VERSION "HIPBNYYYYYYYYYYYYYYYYYYYYYYYYYYYNNNYNNNNNN/4/%%%/4/'%**4NNN///"

NS_ :

BS_:

BU_: NodeD2 NodeC2 NodeB2 NodeA2 NodeD NodeC NodeB NodeA

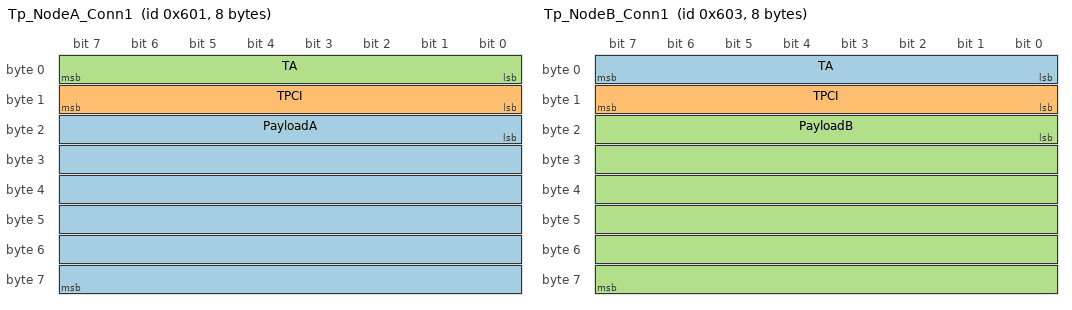
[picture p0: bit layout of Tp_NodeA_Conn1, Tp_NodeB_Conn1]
BO_ 1537 Tp_NodeA_Conn1: 8 NodeA
 SG_ PayloadA : 16|48@1+ (1,0) [0|0] "" Vector__XXX
 SG_ TPCI : 8|8@1+ (1,0) [0|0] "" Vector__XXX
 SG_ TA : 0|8@1+ (1,0) [0|0] "" Vector__XXX

BO_ 1539 Tp_NodeB_Conn1: 8 NodeB
 SG_ TA : 0|8@1+ (1,0) [0|0] "" Vector__XXX
 SG_ TPCI : 8|8@1+ (1,0) [0|0] "" Vector__XXX
 SG_ PayloadB : 16|48@1+ (1,0) [0|0] "" Vector__XXX

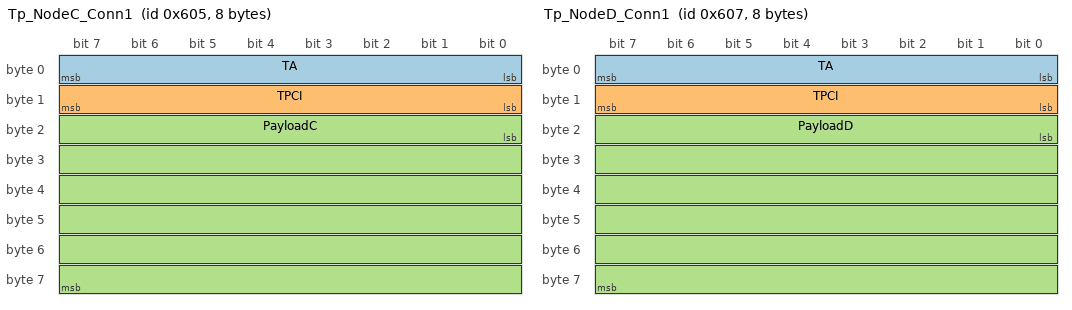
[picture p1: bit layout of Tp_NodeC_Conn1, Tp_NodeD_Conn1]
BO_ 1541 Tp_NodeC_Conn1: 8 NodeC
 SG_ TA : 0|8@1+ (1,0) [0|0] "" Vector__XXX
 SG_ TPCI : 8|8@1+ (1,0) [0|0] "" Vector__XXX
 SG_ PayloadC : 16|48@1+ (1,0) [0|0] "" Vector__XXX

BO_ 1543 Tp_NodeD_Conn1: 8 NodeD
 SG_ TA : 0|8@1+ (1,0) [0|0] "" Vector__XXX
 SG_ TPCI : 8|8@1+ (1,0) [0|0] "" Vector__XXX
 SG_ PayloadD : 16|48@1+ (1,0) [0|0] "" Vector__XXX

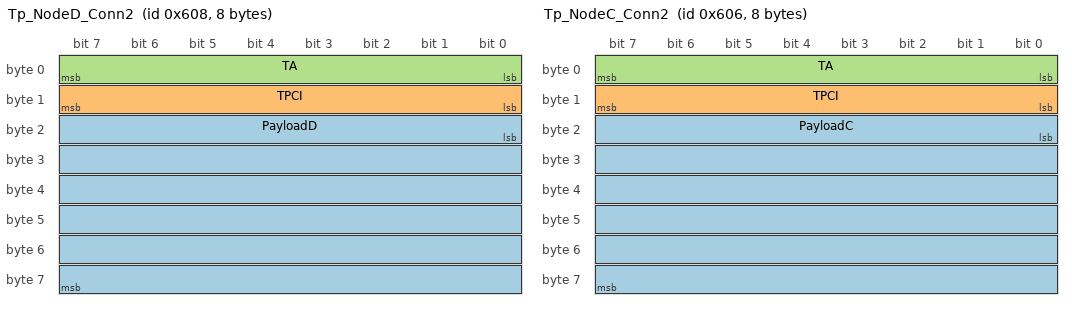
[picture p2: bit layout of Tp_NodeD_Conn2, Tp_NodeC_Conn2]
BO_ 1544 Tp_NodeD_Conn2: 8 NodeD
 SG_ PayloadD : 16|48@1+ (1,0) [0|0] "" Vector__XXX
 SG_ TPCI : 8|8@1+ (1,0) [0|0] "" Vector__XXX
 SG_ TA : 0|8@1+ (1,0) [0|0] "" Vector__XXX

BO_ 1542 Tp_NodeC_Conn2: 8 NodeC
 SG_ PayloadC : 16|48@1+ (1,0) [0|0] "" Vector__XXX
 SG_ TPCI : 8|8@1+ (1,0) [0|0] "" Vector__XXX
 SG_ TA : 0|8@1+ (1,0) [0|0] "" Vector__XXX

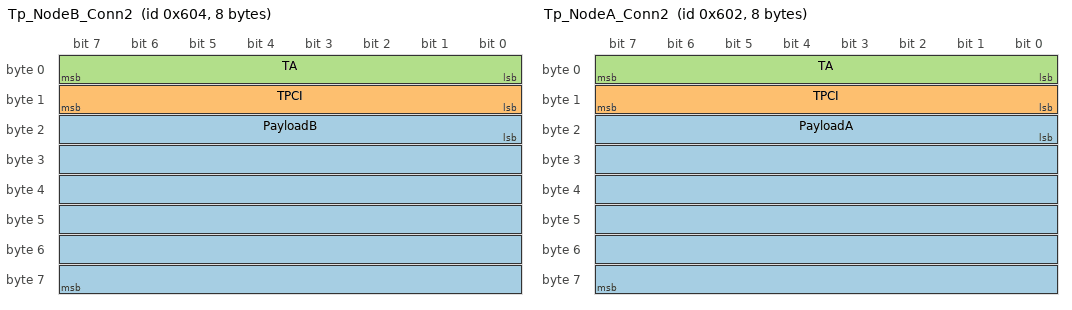
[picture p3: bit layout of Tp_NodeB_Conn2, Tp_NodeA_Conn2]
BO_ 1540 Tp_NodeB_Conn2: 8 NodeB
 SG_ PayloadB : 16|48@1+ (1,0) [0|0] "" Vector__XXX
 SG_ TPCI : 8|8@1+ (1,0) [0|0] "" Vector__XXX
 SG_ TA : 0|8@1+ (1,0) [0|0] "" Vector__XXX

BO_ 1538 Tp_NodeA_Conn2: 8 NodeA
 SG_ PayloadA : 16|48@1+ (1,0) [0|0] "" Vector__XXX
 SG_ TPCI : 8|8@1+ (1,0) [0|0] "" Vector__XXX
 SG_ TA : 0|8@1+ (1,0) [0|0] "" Vector__XXX

BO_TX_BU_ 1537 : NodeA2,NodeA;
BO_TX_BU_ 1539 : NodeB2,NodeB;
BO_TX_BU_ 1541 : NodeC2,NodeC;
BO_TX_BU_ 1543 : NodeD2,NodeD;
BO_TX_BU_ 1544 : NodeD2,NodeD;
BO_TX_BU_ 1542 : NodeC2,NodeC;
BO_TX_BU_ 1540 : NodeB2,NodeB;
BO_TX_BU_ 1538 : NodeA2,NodeA;

CM_ "CAN communication matrix for body electronics
*******************************************************

implemented: turn lights, warning lights, windows


";
CM_ BU_ NodeA2 "Test Transport-Layer with DLL";
CM_ BU_ NodeA "Test Transport-Layer with DLL";
BA_DEF_ BU_  "TpAddressExtension" INT 0 255;
BA_DEF_ BU_  "TpUse2003Ext" INT 0 1;
BA_DEF_ BU_  "NodeLayerModules" STRING ;
BA_DEF_ BU_  "TpTxIdentifier" HEX 0 536870911;
BA_DEF_  "TpBaseAddress" HEX 0 536870911;
BA_DEF_ BU_  "TpRxIdentifier" HEX 0 536870911;
BA_DEF_ BU_  "Diagnose-Stationsadresse" HEX 0 255;
BA_DEF_ BU_  "TpRxMask" HEX 0 65535;
BA_DEF_ BU_  "TpCanBus" INT 1 2;
BA_DEF_ BU_  "TpUseFC" INT 0 1;
BA_DEF_ BU_  "TpNodeBaseAddress" HEX 0 33554431;
BA_DEF_ BU_  "TpTargetAddress" INT 0 255;
BA_DEF_ BU_  "TpSTMin" INT 0 255;
BA_DEF_ BU_  "TpBlockSize" INT 0 255;
BA_DEF_DEF_  "TpAddressExtension" 0;
BA_DEF_DEF_  "TpUse2003Ext" 0;
BA_DEF_DEF_  "NodeLayerModules" "osek_tp.dll";
BA_DEF_DEF_  "TpTxIdentifier" 1;
BA_DEF_DEF_  "TpBaseAddress" 1536;
BA_DEF_DEF_  "TpRxIdentifier" 1;
BA_DEF_DEF_  "Diagnose-Stationsadresse" 0;
BA_DEF_DEF_  "TpRxMask" 255;
BA_DEF_DEF_  "TpCanBus" 1;
BA_DEF_DEF_  "TpUseFC" 1;
BA_DEF_DEF_  "TpNodeBaseAddress" 1536;
BA_DEF_DEF_  "TpTargetAddress" 0;
BA_DEF_DEF_  "TpSTMin" 0;
BA_DEF_DEF_  "TpBlockSize" 0;
BA_ "TpAddressExtension" BU_ NodeD2 29;
BA_ "TpUse2003Ext" BU_ NodeD2 1;
BA_ "TpTxIdentifier" BU_ NodeD2 1544;
BA_ "TpRxIdentifier" BU_ NodeD2 1542;
BA_ "Diagnose-Stationsadresse" BU_ NodeD2 8;
BA_ "TpTargetAddress" BU_ NodeD2 5;
BA_ "TpSTMin" BU_ NodeD2 20;
BA_ "TpBlockSize" BU_ NodeD2 2;
BA_ "TpAddressExtension" BU_ NodeC2 19;
BA_ "TpUse2003Ext" BU_ NodeC2 1;
BA_ "TpTxIdentifier" BU_ NodeC2 1542;
BA_ "TpRxIdentifier" BU_ NodeC2 1544;
BA_ "Diagnose-Stationsadresse" BU_ NodeC2 6;
BA_ "TpTargetAddress" BU_ NodeC2 7;
BA_ "TpSTMin" BU_ NodeC2 200;
BA_ "TpBlockSize" BU_ NodeC2 5;
BA_ "TpAddressExtension" BU_ NodeB2 13;
BA_ "TpUse2003Ext" BU_ NodeB2 1;
BA_ "TpTxIdentifier" BU_ NodeB2 1540;
BA_ "TpRxIdentifier" BU_ NodeB2 1538;
BA_ "Diagnose-Stationsadresse" BU_ NodeB2 4;
BA_ "TpTargetAddress" BU_ NodeB2 1;
BA_ "TpSTMin" BU_ NodeB2 20;
BA_ "TpBlockSize" BU_ NodeB2 2;
BA_ "TpAddressExtension" BU_ NodeA2 7;
BA_ "TpUse2003Ext" BU_ NodeA2 1;
BA_ "TpTxIdentifier" BU_ NodeA2 1538;
BA_ "TpRxIdentifier" BU_ NodeA2 1540;
BA_ "Diagnose-Stationsadresse" BU_ NodeA2 242;
BA_ "TpTargetAddress" BU_ NodeA2 3;
BA_ "TpSTMin" BU_ NodeA2 20;
BA_ "TpBlockSize" BU_ NodeA2 2;
BA_ "TpAddressExtension" BU_ NodeD 29;
BA_ "TpUse2003Ext" BU_ NodeD 1;
BA_ "TpTxIdentifier" BU_ NodeD 1543;
BA_ "TpRxIdentifier" BU_ NodeD 1541;
BA_ "Diagnose-Stationsadresse" BU_ NodeD 7;
BA_ "TpSTMin" BU_ NodeD 20;
BA_ "TpBlockSize" BU_ NodeD 2;
BA_ "TpTargetAddress" BU_ NodeD 5;
BA_ "TpAddressExtension" BU_ NodeC 19;
BA_ "TpUse2003Ext" BU_ NodeC 1;
BA_ "TpSTMin" BU_ NodeC 200;
BA_ "TpBlockSize" BU_ NodeC 5;
BA_ "Diagnose-Stationsadresse" BU_ NodeC 5;
BA_ "TpRxIdentifier" BU_ NodeC 1543;
BA_ "TpTxIdentifier" BU_ NodeC 1541;
BA_ "TpTargetAddress" BU_ NodeC 7;
BA_ "TpAddressExtension" BU_ NodeB 13;
BA_ "TpUse2003Ext" BU_ NodeB 1;
BA_ "TpTxIdentifier" BU_ NodeB 1539;
BA_ "TpRxIdentifier" BU_ NodeB 1537;
BA_ "Diagnose-Stationsadresse" BU_ NodeB 3;
BA_ "TpSTMin" BU_ NodeB 20;
BA_ "TpBlockSize" BU_ NodeB 2;
BA_ "TpTargetAddress" BU_ NodeB 1;
BA_ "TpAddressExtension" BU_ NodeA 7;
BA_ "TpUse2003Ext" BU_ NodeA 1;
BA_ "TpBlockSize" BU_ NodeA 2;
BA_ "TpSTMin" BU_ NodeA 20;
BA_ "TpTxIdentifier" BU_ NodeA 1537;
BA_ "TpRxIdentifier" BU_ NodeA 1539;
BA_ "Diagnose-Stationsadresse" BU_ NodeA 241;
BA_ "TpTargetAddress" BU_ NodeA 3;
